# K32W041AM register map
Vendor: nxp.com; File version: 1.0
CPU: CM4 r0p1, little endian, MPU, no FPU, VTOR, 3 interrupt priority bits
Registers are 32-bit, read-write, reset 0x0 unless marked. A register's access mark holds for its fields unless they carry their own. Offsets are from the block's base; [hi:lo] are bit positions; {n}, {i} and the like mark numbered series.

## ISO7816 — This is the description of component iso7816 It is an ISO7816 controller with APB bus interface. More details will follow.
Base 0x40006000
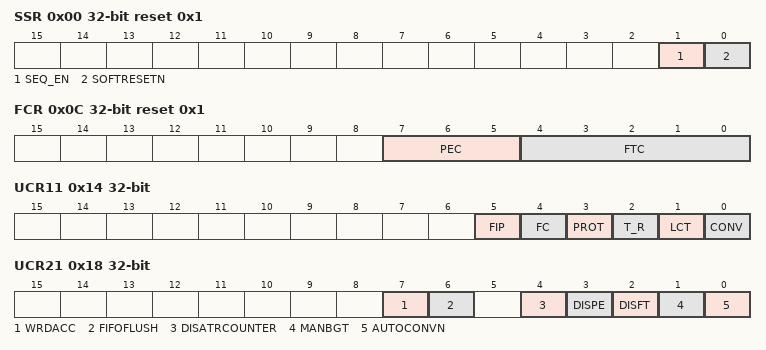
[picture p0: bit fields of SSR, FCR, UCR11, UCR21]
0x00 SSR reset 0x1 (reset mask 0x1) — Slot Select Register
  [1] SEQ_EN — Set this bit to enable the sequencer. If this field is 0b, the sequencer will not respond to the Start control bit.
  [0] SOFTRESETN — When set to logic 0 this bit resets the whole Contact UART (software reset), sets to logic 1 automatically by hardware after after one clock cycle if slot 1 is not activated else after one clock cycle after slot 1 has been automatically deactivated. Software should check soft reset is finished by reading SSR register before any further action.
0x04 PDR1_LSB reset 0x74 — Programmable Divider Register (LSB) slot 1. Least significant byte of a 16-bit counter defining the ETU. The ETU counter counts a number of cycles of the Contact Interface clock, this defines the ETU. The minimum acceptable value is 0001 0000b.
0x08 PDR1_MSB reset 0x1 — Programmable Divider Register (MSB) slot 1. Most significant byte of a 16-bit counter defining the ETU. The ETU counter counts a number of cycles of the Contact Interface clock, this defines the ETU
0x0C FCR reset 0x1 — FIFO Control Register
  [7:5] PEC — Parity Error Count [For protocol T = 0] Set the number of allowed repetitions in reception or transmission mode before setting pe in ct_usr1_reg. The value 000 indicates that, if only one parity error has occurred, bit pe is set at logic 1; the value 111 indicates that bit pe will be set at logic 1 after 8 parity errors. If a correct character is received before the programmed error number is reached, the error counter will be reset. If the programmed number of allowed parity errors is reached, bit pe in register ct_usr1_reg will be set at logic 1. If a transmitted character has been naked by the card, then the Contact UART will automatically retransmit it up to a number of times equal to the value programmed in bits PEC(2:0); the character will be resent at 15 ETU. If a transmitted character is considered as correct by the card after having been naked a number of times less than the value programmed in bits PEC(2:0) +1, the error counter will be reset. If a transmitted has been naked by the card a number of times equal to the value programmed in bits PEC(2:0) +1, the transmission stops and bit pe in register ct_usr1_reg is set at logic 1. The firmware is supposed to deactivate the card. If not, the firmware has the possibility to pursue the transmission. By reading the number of bytes present into the FIFO (ffl bits), it can determine which character has been naked PEC +1 times by the card. It will then flush the FIFO (FIFO flush bit). The next step consits in unlocking the transmission using dispe bit. By writing this bit at logic level one (and then at logic level zero if the firmware still wants to check parity errors), the transmission is unlocked. The firmware can now write bytes into the FIFO. In transmission mode, if bits PEC(2:0) are at logic 0, then the automatic retransmission is invalidated. There is no retransmission; the transmission continues with the next character sent at 13 ETU. [For protocol T = 1]: The error counter has no action: bit pe is set at logic 1 at the first wrong received character.
  [4:0] FTC — FIFO Threshold Configuration: Define the number of received or transmitted characters in the FIFO triggering the ft bit in USR1. The FIFO depth is 32 bytes. In reception mode, it enables to know that a number equals to ftc(4:0) + 1 bytes have been received. In transmission mode, ftc(4:0) equals to the number of remaining bytes into the FIFO. Be careful: in reception mode 00000 = length 1, and in transmission mode 00000 = length 0.
0x10 GTR1 — Guard Time Register slot 1. Value used by the Contact UART notably in transmission mode. The Contact UART will wait this number of ETUs before transmitting the character. In protocol T=1, gtr = FFh means operation at 11 ETUs. In protocol T=0, gtr = FFh means operation at 12 ETUs.
0x14 UCR11 — UART Configuration Register 1 slot 1
  [5] FIP — Force Inverse Parity: If bit FIP is set to logic 1, the Contact UART will NAK a correctly received character, and will transmit characters with wrong parity bits.
  [4] FC — Described in a separated document.
  [3] PROT — PROTocol: Selects the protocol: logic 1 means T=1 and logic 0 T=0.
  [2] T_R — Transmit/Receive: Defines the mode: logic 1 means transmission and logic 0 reception. Bit T/R is set by software for transmission mode. Bit T/R is automatically reset to logic 0 by hardware, if bit LCT has been used before transmitting the last character. Note that when switching from/to reception to/from transmission mode, the FIFO is flushed. Any remaining bytes are lost.
  [1] LCT — Last Character to Transmit: Bit LCT is set to logic 1 by software before writing the last character to be transmitted in register ct_utr_reg. It allows automatic change to reception mode. It is reset to logic 0 by hardware at the end of a successful transmission after 11.75 ETUs in protocol T = 0 and after 10.75 ETUs in protocol T = 1. When bit LCT is being reset to logic 0, bit T/R is also reset to logic 0 and the UART is ready to receive a character. LCT bit can be set to logic 1 by software not only when writing the last character to be transmitted but also during the transmission or even at the beginning of the transmission. It will be taken into account when the FIFO becomes empty, which implies for the software to be able to regularly re-load the FIFO when transmitting more than 32 bytes to ensure there is at least one byte into the FIFO as long as the transmission is not finished. Else, a switch to reception mode will prematurely occur before having transmitted all the bytes.
  [0] CONV — CONVention: Bit CONV is set to logic 1 if the convention is direct. Bit CONV is either automatically written by hardware according to the convention detected during ATR, or by software if the bit AUTOCONV in register ct_ucr1_reg is set to logic 1.
0x18 UCR21 — UART Configuration Register 2 slot 1
  [7] WRDACC — FIFO WoRD ACCess: When set to logic 1, the FIFO supports word (4 bytes) access (read and write), access failure is indicated by bit wrdaccerr in register USR2. When set to logic 0, the FIFO supports byte access (read and write).
  [6] FIFOFLUSH — FIFO flush: When set to logic 1, the FIFO is flushed whatever the mode (reception or transmission) is. It can be used before any reception or transmission of characters but not while receiving or transmitting a character. It is reset to logic 0 by hardware after one clk_ip cycle.
  [4] DISATRCOUNTER — DISable ATR counter: [For Slot 1 only] When set to logic 1 the bits EARLY and MUTE in register ct_usr1_reg will not generate interrupt. This bit should be set before activating.
  [3] DISPE — DISable Parity Error interrupt bit: When set to logic 1, the parity is not checked in both reception and transmission modes, the bit pe in register ct_usr1_reg will not generate interrupt.
  [2] DISFT — DISable Fifo Threshold interrupt bit: When set to logic 1 the bit ft in register ct_usr1_reg will not generate interrupt.
  [1] MANBGT — MANual BGT: When set to logic 1, BGT is managed by software, else by hardware.
  [0] AUTOCONVN — AUTOmatically detected CONVention: If bit AUTOCONV = 1, then the convention is set by software using bit CONV in register ct_ucr1_reg. If the bit is reset to logic 0, then the configuration is automatically detected on the first received character and the bit automatically set after convention detection.
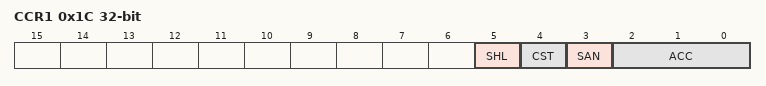
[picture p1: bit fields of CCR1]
0x1C CCR1 — Clock Configuration Register slot 1
  [5] SHL — Stop HIGH or LOW: - Slot 1: If bits SAN = 0 and CST = 1, then the clock is stopped at LOW level. If bit SHL = 0, and at HIGH level if bit SHL = 1. I+I10f bit SAN = 1, then contact CLK is the copy of the value of bit SHL.
  [4] CST — Clock STop: [For Slot 1]: In the case of an asynchronous card, bit CST defines whether the clock to the card is stopped or not; if bit CST is reset to logic 0, then the clock is determined by bits ACC0, ACC1 and ACC2. [For Slot AUX]+I40: This bit is not available for the auxiliary slot (ct_ccr2_reg) since clock stop feature is supported using CLKAUXen bit in ct_ssr_reg register.
  [3] SAN — Synchronous/Asynchronous Card: [For Slot 1]: When set to logic 1, the Contact UART supports synchronous card. The Contact UART is then bypassed, only bit 0 of registers ct_urr_reg and ct_utr_reg is connected to pin I/O. In this case, the card clock is controlled by bit SHL and RST card is controlled by bit RSTIN in register ct_pcr_reg. When set to logic 0, the Contact UART supports asynchronous card. Dynamic change (while activated) is not supported. The choice should be done before activating the card. [For Slot AUX]: When set to logic 1, the Contact UART supports synchronous card. The Contact UART is then bypassed, only bit 0 of registers ct_urr_reg and ct_utr_reg is connected to pin I/O. In this case, the card clock is controlled by bit SHL. When set to logic 0, the Contact UART supports asynchronous card. Dynamic change (while CLKAUXen = 1) is not supported. The choice should be done before enabling CLKAUX clock.
  [2:0] ACC — Asynchronous Card Clock: Defines the card clock frequency: 000: card clock frequency = fclk_ip; 001: card clock frequency = fclk_ip /2; 010: card clock frequency = fclk_ip /3; 011: card clock frequency = fclk_ip /4; 100: card clock frequency = fclk_ip /5; 101: card clock frequency = fclk_ip /6; 110: card clock frequency = fclk_ip /8; 111: card clock frequency = fclk_ip /16. All frequency changes are synchronous, thus ensuring that no spikes or unwanted pulse widths occur during changes. In conjunction with registers ct_etucr_lsb_reg and ct_etucr_msb_reg, the bits ACC2, ACC1 and ACC0 defines the baudrate used by the Contact UART.
0x20 PCR reset 0xC0 — Power Control Register
0x24 ECR reset 0xAA — Early answer Counter register
0x28 MCRL_LSB reset 0x74 — Mute card Counter RST Low register (LSB)
0x2C MCRL_MSB reset 0xA4 — Mute card Counter RST Low register (MSB)
0x30 MCRH_LSB reset 0x74 — Mute card Counter RST High register (LSB)
0x34 MCRH_MSB reset 0xA4 — Mute card Counter RST High register (MSB)
0x3C URR_UTR — UART Receive Register / UART Transmit Register
{0x48+4i} TOR{i} wo (i=1..3) — Time-Out Register {i}
0x58 TOC — Time-Out Configuration register
0x5C FSR ro — FIFO Status Register
0x60 MSR ro reset 0x2 — Mixed Status Register
0x64 USR1 ro — UART Status Register 1
0x68 USR2 ro — UART Status Register 2

## Notices in the file
Copyright 2016-2020 NXP
All rights reserved.
SPDX-License-Identifier: BSD-3-Clause
